# f2838x_cpu_sys_regs register map
Vendor: Texas Instruments
Peripheral module from a debugger description file (folder C2000).
Address unit: 16 bits
Registers are 32-bit, read-write, no defined reset value unless marked. A register's access mark holds for its fields unless they carry their own. Offsets are as the file gives them; lines under a group give offsets from that group; [hi:lo] are bit positions; {n}, {i} and the like mark numbered series; 'fields as' and 'values as' point back to an identical list; <NAME> marks a mode.

## CPU_SYS_REGS — CPU SYS Registers
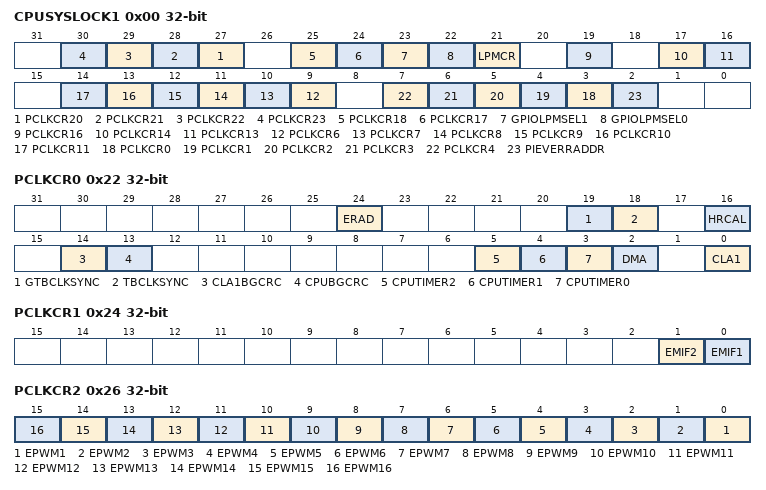
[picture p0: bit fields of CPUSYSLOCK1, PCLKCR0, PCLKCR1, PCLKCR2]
0x00 CPUSYSLOCK1 — Lock bit for CPUSYS registers
  [n+7] PCLKCR{n} (n=20..23) — Lock bit for PCLKCR{n} Register
  [25] PCLKCR18 — Lock bit for PCLKCR18 Register
  [24] PCLKCR17 — Lock bit for PCLKCR17 Register
  [23] GPIOLPMSEL1 — Lock bit for GPIOLPMSEL1 Register
  [22] GPIOLPMSEL0 — Lock bit for GPIOLPMSEL0 Register
  [21] LPMCR — Lock bit for LPMCR Register
  [19] PCLKCR16 — Lock bit for PCLKCR16 Register
  [17] PCLKCR14 — Lock bit for PCLKCR14 Register
  [16] PCLKCR13 — Lock bit for PCLKCR13 Register
  [n+3] PCLKCR{n} (n=6..11) — Lock bit for PCLKCR{n} Register
  [n+3] PCLKCR{n} (n=0..4) — Lock bit for PCLKCR{n} Register
  [2] PIEVERRADDR — Lock bit for PIEVERRADDR Register
0x02 CPUSYSLOCK2 — Lock bit for CPUSYS registers
  [0] ETHERCATCTL — Lock bit for ETHERCATCTL register
0x0A PIEVERRADDR — PIE Vector Fetch Error Address register
  [21:0] ADDR — PIE Vector Fetch Error Handler Routine Address
0x0C ETHERCATCTL — ETHERCAT control register.
  [0] I2CLOOPBACK — Loopback I2C port of etherCAT IP to I2C_A.
0x22 PCLKCR0 — Peripheral Clock Gating Registers
  [24] ERAD — ERAD module clock enable
  [19] GTBCLKSYNC — EPWM Time Base Clock Global sync
  [18] TBCLKSYNC — EPWM Time Base Clock sync
  [16] HRCAL — HRCAL Clock Enable Bit
  [14] CLA1BGCRC — CLA1BGCRC Clock Enable Bit
  [13] CPUBGCRC — CPUBGCRC Clock Enable Bit
  [5] CPUTIMER2 — CPUTIMER2 Clock Enable bit
  [4] CPUTIMER1 — CPUTIMER1 Clock Enable bit
  [3] CPUTIMER0 — CPUTIMER0 Clock Enable bit
  [2] DMA — DMA Clock Enable bit
  [0] CLA1 — CLA1 Clock Enable Bit
0x24 PCLKCR1 — Peripheral Clock Gating Registers
  [1] EMIF2 — EMIF2 Clock Enable bit
  [0] EMIF1 — EMIF1 Clock Enable bit
0x26 PCLKCR2 — Peripheral Clock Gating Registers
  [n-1] EPWM{n} (n=1..16) — EPWM{n} Clock Enable bit
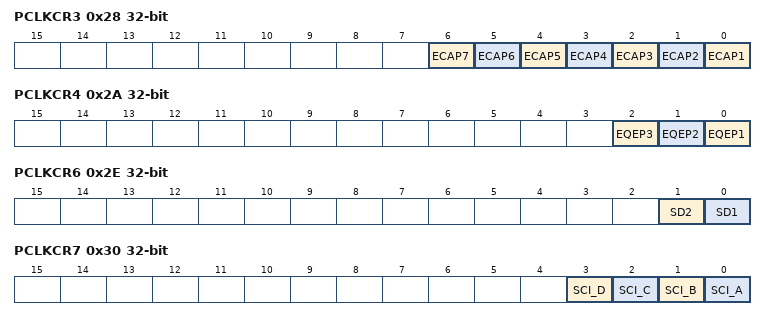
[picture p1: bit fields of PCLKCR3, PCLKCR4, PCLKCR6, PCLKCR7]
0x28 PCLKCR3 — Peripheral Clock Gating Registers
  [n-1] ECAP{n} (n=1..7) — ECAP{n} Clock Enable bit
0x2A PCLKCR4 — Peripheral Clock Gating Registers
  [2] EQEP3 — EQEP3 Clock Enable bit
  [1] EQEP2 — EQEP2 Clock Enable bit
  [0] EQEP1 — EQEP1 Clock Enable bit
0x2E PCLKCR6 — Peripheral Clock Gating Registers
  [1] SD2 — SD2 Clock Enable bit
  [0] SD1 — SD1 Clock Enable bit
0x30 PCLKCR7 — Peripheral Clock Gating Registers
  [3] SCI_D — SCI_D Clock Enable bit
  [2] SCI_C — SCI_C Clock Enable bit
  [1] SCI_B — SCI_B Clock Enable bit
  [0] SCI_A — SCI_A Clock Enable bit
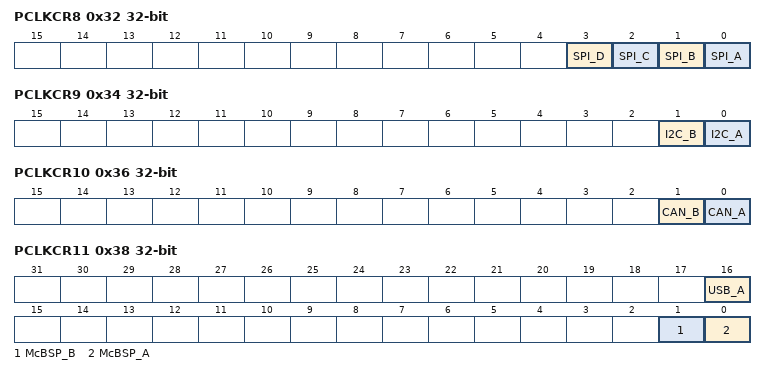
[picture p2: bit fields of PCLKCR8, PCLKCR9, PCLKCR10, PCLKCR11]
0x32 PCLKCR8 — Peripheral Clock Gating Registers
  [3] SPI_D — SPI_D Clock Enable bit
  [2] SPI_C — SPI_C Clock Enable bit
  [1] SPI_B — SPI_B Clock Enable bit
  [0] SPI_A — SPI_A Clock Enable bit
0x34 PCLKCR9 — Peripheral Clock Gating Registers
  [1] I2C_B — I2C_B Clock Enable bit
  [0] I2C_A — I2C_A Clock Enable bit
0x36 PCLKCR10 — Peripheral Clock Gating Registers
  [1] CAN_B — CAN_B Clock Enable bit
  [0] CAN_A — CAN_A Clock Enable bit
0x38 PCLKCR11 — Peripheral Clock Gating Registers
  [16] USB_A — USB_A Clock Enable bit
  [1] McBSP_B — McBSP_B Clock Enable bit
  [0] McBSP_A — McBSP_A Clock Enable bit
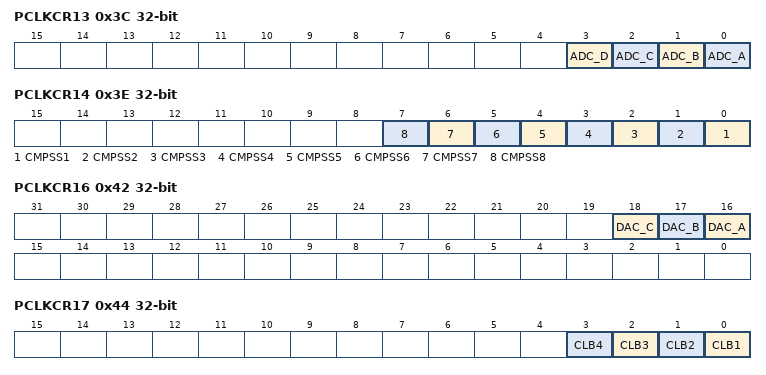
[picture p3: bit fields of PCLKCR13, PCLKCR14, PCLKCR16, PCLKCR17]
0x3C PCLKCR13 — Peripheral Clock Gating Registers
  [3] ADC_D — ADC_D Clock Enable bit
  [2] ADC_C — ADC_C Clock Enable bit
  [1] ADC_B — ADC_B Clock Enable bit
  [0] ADC_A — ADC_A Clock Enable bit
0x3E PCLKCR14 — Peripheral Clock Gating Registers
  [n-1] CMPSS{n} (n=1..8) — CMPSS{n} Clock Enable bit
0x42 PCLKCR16 — Peripheral Clock Gating Registers
  [18] DAC_C — Buffered_DAC12_3 Clock Enable Bit
  [17] DAC_B — Buffered_DAC12_2 Clock Enable Bit
  [16] DAC_A — Buffered_DAC12_1 Clock Enable Bit
0x44 PCLKCR17 — Peripheral Clock Gating Registers
  [n-1] CLB{n} (n=1..4) — CLB{n} Clock Enable bit
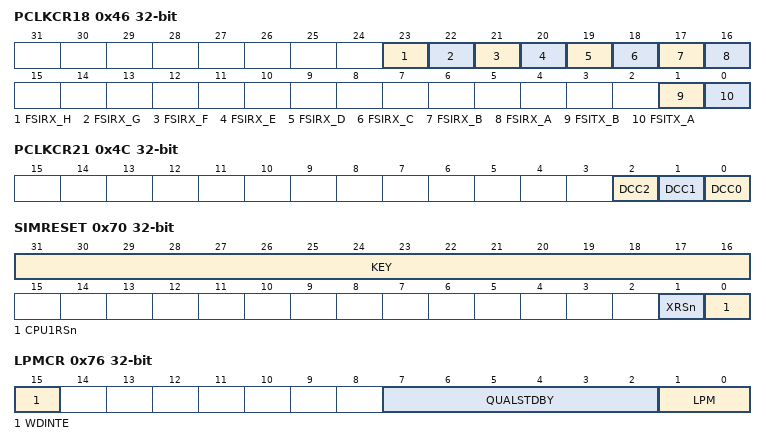
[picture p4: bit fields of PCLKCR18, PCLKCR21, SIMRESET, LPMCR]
0x46 PCLKCR18 — Peripheral Clock Gating Registers
  [23] FSIRX_H — FSIRX_H Clock Enable bit
  [22] FSIRX_G — FSIRX_G Clock Enable bit
  [21] FSIRX_F — FSIRX_F Clock Enable bit
  [20] FSIRX_E — FSIRX_E Clock Enable bit
  [19] FSIRX_D — FSIRX_D Clock Enable bit
  [18] FSIRX_C — FSIRX_C Clock Enable bit
  [17] FSIRX_B — FSIRX_B Clock Enable bit
  [16] FSIRX_A — FSIRX_A Clock Enable bit
  [1] FSITX_B — FSITX_B Clock Enable bit
  [0] FSITX_A — FSITX_A Clock Enable bit
0x4A PCLKCR20 — Peripheral Clock Gating Registers
  [0] PMBUS_A — PMBUS_A Clock Enable bit
0x4C PCLKCR21 — Peripheral Clock Gating Registers
  [2] DCC2 — DCC2 Clock Enable Bit
  [1] DCC1 — DCC1 Clock Enable Bit
  [0] DCC0 — DCC0 Clock Enable Bit
0x4E PCLKCR22 — Peripheral Clock Gating Registers
  [0] PBISTCLK — PBISTCLK Clock Enable Bit
0x50 PCLKCR23 — Peripheral Clock Gating Registers
  [0] ETHERCAT — ETHERCAT Clock Enable Bit
0x70 SIMRESET — Simulated Reset Register
  [31:16] KEY — Key value
  [1] XRSn — Generates a simulated XRSn
  [0] CPU1RSn — Generates a reset to CPU
0x76 LPMCR — LPM Control Register
  [15] WDINTE — Enable for WDINT wakeup from STANDBY
  [7:2] QUALSTDBY — STANDBY Wakeup Pin Qualification Setting
  [1:0] LPM — Low Power Mode setting
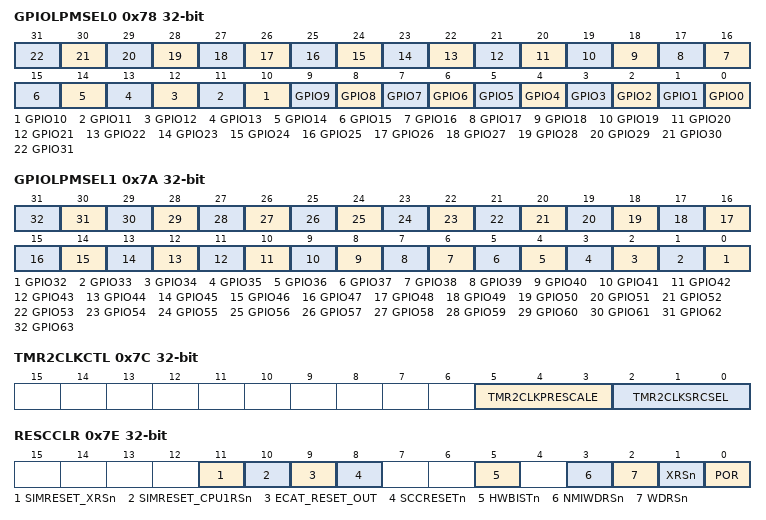
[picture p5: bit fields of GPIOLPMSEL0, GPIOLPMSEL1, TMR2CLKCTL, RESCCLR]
0x78 GPIOLPMSEL0 — GPIO LPM Wakeup select registers
  [n] GPIO{n} (n=0..31) — GPIO{n} Enable for LPM Wakeup
0x7A GPIOLPMSEL1 — GPIO LPM Wakeup select registers
  [n-32] GPIO{n} (n=32..63) — GPIO{n} Enable for LPM Wakeup
0x7C TMR2CLKCTL — Timer2 Clock Measurement functionality control register
  [5:3] TMR2CLKPRESCALE — CPU Timer 2 Clock Pre-Scale Value
  [2:0] TMR2CLKSRCSEL — CPU Timer 2 Clock Source Select Bit
0x7E RESCCLR — Reset Cause Clear Register
  [11] SIMRESET_XRSn — SIMRESET_XRSn Reset Cause Indication Bit
  [10] SIMRESET_CPU1RSn — SIMRESET_CPU1RSn Reset Cause Indication Bit
  [9] ECAT_RESET_OUT — ECAT_RESET_OUT Reset Cause Indication Bit
  [8] SCCRESETn — SCCRESETn Reset Cause Indication Bit
  [5] HWBISTn — HWBISTn Reset Cause Indication Bit
  [3] NMIWDRSn — NMIWDRSn Reset Cause Indication Bit
  [2] WDRSn — WDRSn Reset Cause Indication Bit
  [1] XRSn — XRSn Reset Cause Indication Bit
  [0] POR — POR Reset Cause Indication Bit
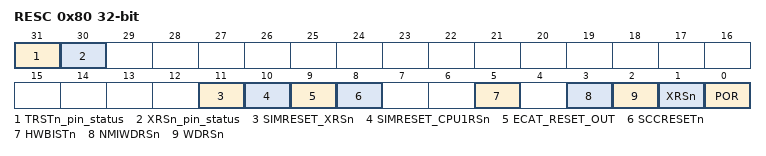
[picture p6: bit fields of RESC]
0x80 RESC access per field — Reset Cause register
  [31] TRSTn_pin_status ro — TRSTn Status
  [30] XRSn_pin_status ro
  [11] SIMRESET_XRSn rw — SIMRESET_XRSn Reset Cause Indication Bit
  [10] SIMRESET_CPU1RSn rw — SIMRESET_CPU1RSn Reset Cause Indication Bit
  [9] ECAT_RESET_OUT rw — ECAT_RESET_OUT Reset Cause Indication Bit
  [8] SCCRESETn rw — SCCRESETn Reset Cause Indication Bit
  [5] HWBISTn rw — HWBISTn Reset Cause Indication Bit
  [3] NMIWDRSn rw — NMIWDRSn Reset Cause Indication Bit
  [2] WDRSn rw — WDRSn Reset Cause Indication Bit
  [1] XRSn rw — XRSn Reset Cause Indication Bit
  [0] POR rw — POR Reset Cause Indication Bit
